AUTOSAR XML (schema 4-3-0)
package /ComponentTypes
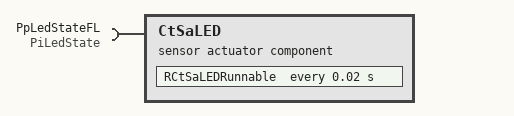
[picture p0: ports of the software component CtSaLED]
  sensor actuator sw component type CtSaLED
    require port PpLedStateFL: nonqueued-receiver-com-spec{data-element=DePiLedState, filter=data-filter-type=ALWAYS, init-value=0}, required-interface=PiLedState
    behavior CtSaLED_InternalBehavior
      timing event TMT_Runnable: start-on-event=RCtSaLEDRunnable, period=0.02
      runnable RCtSaLEDRunnable
        data-receive-point-by-arguments:
          access REC_PpLedStateFL_DePiLedState: accessed-variable=PpLedStateFL.DePiLedState
  swc implementation CtSaLED_Implementation: behavior=CtSaLED_InternalBehavior
